VERSION ""

NS_ :

BS_:

BU_: Car RES Datalogger
VAL_TABLE_ DL_Status 8 "Error" 7 "Logging EM & FSD data" 5 "Logging FSD data" 3 "Logging EM data" 1 "DL idle, ready to log" ;

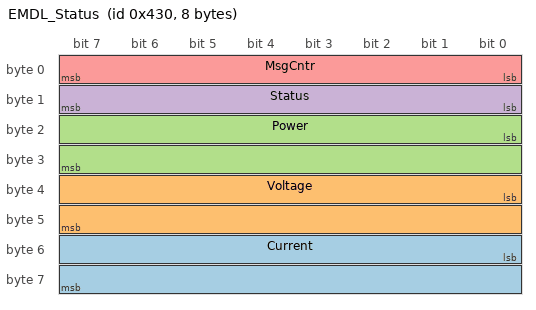
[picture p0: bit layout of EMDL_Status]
BO_ 1072 EMDL_Status: 8 Datalogger
 SG_ Current : 48|16@1- (0.05,0) [-1638.4|1638.35] "A" Vector__XXX
 SG_ Voltage : 32|16@1- (0.04,0) [-1310.72|1310.68] "V" Vector__XXX
 SG_ Power : 16|16@1- (3,0) [-98304|98301] "W" Vector__XXX
 SG_ Status : 8|8@1+ (1,0) [0|255] "" Vector__XXX
 SG_ MsgCntr : 0|8@1+ (1,0) [0|255] "" Vector__XXX

BA_DEF_  "baudrate" INT 500000 500000;
BA_DEF_ SG_  "GenSigSendType" ENUM  "Cyclic","OnWrite","OnWriteWithRepetition","OnChange","OnChangeWithRepetition","IfActive","IfActiveWithRepetition","NoSigSendType","NotUsed","NotUsed","NotUsed","NotUsed","NotUsed";
BA_DEF_ BO_  "GenMsgCycleTime" INT 0 50000;
BA_DEF_  "BusType" STRING ;
BA_DEF_DEF_  "baudrate" 500000;
BA_DEF_DEF_  "GenSigSendType" "Cyclic";
BA_DEF_DEF_  "GenMsgCycleTime" 0;
BA_DEF_DEF_  "BusType" "CAN";
BA_ "GenMsgCycleTime" BO_ 1072 20;
VAL_ 1072 Status 8 "Fault" 7 "Logging Electric & Drvless data" 5 "Logging Driverless data" 3 "Logging Electric data" 1 "EMDL idle, ready to log" ;
